# ATmega16HVA register map
Vendor: Atmel; File version: 1.0
CPU: other r0p0, little endian, no MPU, no FPU, 4 interrupt priority bits
Registers are 8-bit, read-write, reset 0x0 unless marked. A register's access mark holds for its fields unless they carry their own. Offsets are from the block's base; [hi:lo] are bit positions.

## EXINT — External Interrupts
Base 0x0080003C
0x00 EIFR — External Interrupt Flag Register (read-only for debugger)
  [2:0] INTF — External Interrupt Flags
0x01 EIMSK — External Interrupt Mask Register
  [2:0] INT — External Interrupt Request 2 Enable
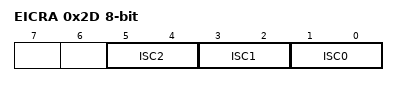
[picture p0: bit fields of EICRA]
0x2D EICRA — External Interrupt Control Register
  [all] fields
    0=LOW_LEVEL_OF_INTX; 1=ANY_LOGICAL_CHANGE_OF_INTX; 2=FALLING_EDGE_OF_INTX; 3=RISING_EDGE_OF_INTX
  [5:4] ISC2 — External Interrupt Sense Control 2 Bits
  [3:2] ISC1 — External Interrupt Sense Control 1 Bits
  [1:0] ISC0 — External Interrupt Sense Control 0 Bits

## FET — FET Control
Base 0x008000F0
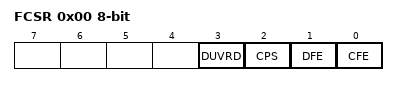
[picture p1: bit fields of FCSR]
0x00 FCSR — FET Control and Status Register
  [3] DUVRD — Deep Under-Voltage Recovery Disable
  [2] CPS — Current Protection Status
  [1] DFE — Discharge FET Enable
  [0] CFE — Charge FET Enable

## FUSE — Fuses
Base 0x00800000
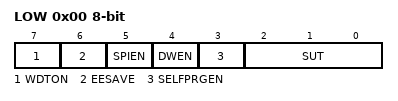
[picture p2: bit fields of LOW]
0x00 LOW
  [7] WDTON — Watch-dog Timer always on
  [6] EESAVE — Preserve EEPROM through the Chip Erase cycle
  [5] SPIEN — Serial program downloading (SPI) enabled
  [4] DWEN — Debug Wire enable
  [3] SELFPRGEN — Self Programming enable
  [2:0] SUT — Select start-up time
    0=6CK_14CK_4MS (Start-up time 6 CK/14 CK + 4 ms); 1=6CK_14CK_8MS (Start-up time 6 CK/14 CK + 8 ms); 2=6CK_14CK_16MS (Start-up time 6 CK/14 CK + 16 ms); 3=6CK_14CK_32MS (Start-up time 6 CK/14 CK + 32 ms); 4=6CK_14CK_64MS (Start-up time 6 CK/14 CK + 64 ms); 5=6CK_14CK_128MS (Start-up time 6 CK/14 CK + 128 ms); 6=6CK_14CK_256MS (Start-up time 6 CK/14 CK + 256 ms); 7=6CK_14CK_512MS (Start-up time 6 CK/14 CK + 512 ms)

## LOCKBIT — Lockbits
Base 0x00800000
0x00 LOCKBIT
  [1:0] LB — Memory Lock
    0=PROG_VER_DISABLED (Further programming and verification disabled); 2=PROG_DISABLED (Further programming disabled); 3=NO_LOCK (No memory lock features enabled)

## PORTA — I/O Port
Base 0x00800020
0x00 PINA — Port A Input Pins (read-only for debugger)
0x01 DDRA — Port A Data Direction Register
0x02 PORTA — Port A Data Register

## PORTB — I/O Port
Base 0x00800023
0x00 PINB — Input Pins, Port B (read-only for debugger)
0x01 DDRB — Data Direction Register, Port B
0x02 PORTB — Data Register, Port B

## PORTC — I/O Port
Base 0x00800026
0x00 PINC — Port C Input Pins (read-only for debugger)
0x02 PORTC — Port C Data Register

## SPI — Serial Peripheral Interface
Base 0x0080004C
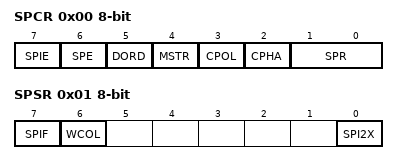
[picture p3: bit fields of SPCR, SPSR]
0x00 SPCR — SPI Control Register
  [7] SPIE — SPI Interrupt Enable
  [6] SPE — SPI Enable
  [5] DORD — Data Order
  [4] MSTR — Master/Slave Select
  [3] CPOL — Clock polarity
  [2] CPHA — Clock Phase
  [1:0] SPR — SPI Clock Rate Selects
    0=FOSC_4; 1=FOSC_16; 3=FOSC_128
0x01 SPSR — SPI Status Register (read-only for debugger)
  [7] SPIF — SPI Interrupt Flag
  [6] WCOL — Write Collision Flag
  [0] SPI2X — Double SPI Speed Bit
0x02 SPDR — SPI Data Register (write-only for debugger)

## TC0 — Timer/Counter, 16-bit
Base 0x00800035
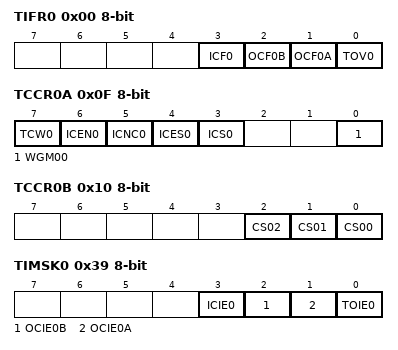
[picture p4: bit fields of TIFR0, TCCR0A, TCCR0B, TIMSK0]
0x00 TIFR0 — Timer/Counter Interrupt Flag register (read-only for debugger)
  [3] ICF0 — Timer/Counter Interrupt Flag Register
  [2] OCF0B — Output Compare Flag
  [1] OCF0A — Output Compare Flag
  [0] TOV0 — Overflow Flag
0x0F TCCR0A — Timer/Counter0 Control Register
  [7] TCW0 — Timer/Counter Width
  [6] ICEN0 — Input Capture Mode Enable
  [5] ICNC0 — Input Capture Noise Canceler
  [4] ICES0 — Input Capture Edge Select
  [3] ICS0 — Input Capture Select
  [0] WGM00 — Clock Select0 bit 0
0x10 TCCR0B — Timer/Counter0 Control Register
  [2] CS02 — Clock Select0 bit 2
  [1] CS01 — Clock Select0 bit 1
  [0] CS00 — Clock Select0 bit 0
0x11 TCNT0 16-bit (reset mask 0xFF) — Timer Counter 0 Bytes
0x13 OCR0A — Output compare Register A
0x14 OCR0B — Output compare Register B
0x39 TIMSK0 — Timer/Counter Interrupt Mask Register
  [3] ICIE0 — Timer/Counter n Input Capture Interrupt Enable
  [2] OCIE0B — Output Compare Interrupt Enable
  [1] OCIE0A — Output Compare Interrupt Enable
  [0] TOIE0 — Overflow Interrupt Enable

## TC1 — Timer/Counter, 16-bit
Base 0x00800036
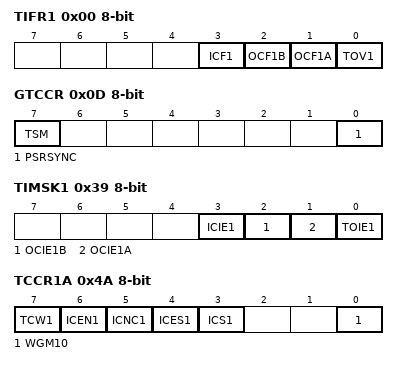
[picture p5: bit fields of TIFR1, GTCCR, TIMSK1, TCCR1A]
0x00 TIFR1 — Timer/Counter Interrupt Flag register (read-only for debugger)
  [3] ICF1 — Timer/Counter 1 Input Capture Flag
  [2] OCF1B — Timer/Counter1 Output Compare Flag B
  [1] OCF1A — Timer/Counter1 Output Compare Flag A
  [0] TOV1 — Timer/Counter1 Overflow Flag
0x0D GTCCR — General Timer/Counter Control Register
  [7] TSM — Timer/Counter Synchronization Mode
  [0] PSRSYNC — Prescaler Reset
0x39 TIMSK1 — Timer/Counter Interrupt Mask Register
  [3] ICIE1 — Timer/Counter n Input Capture Interrupt Enable
  [2] OCIE1B — Timer/Counter1 Output Compare B Interrupt Enable
  [1] OCIE1A — Timer/Counter1 Output Compare A Interrupt Enable
  [0] TOIE1 — Timer/Counter1 Overflow Interrupt Enable
0x4A TCCR1A — Timer/Counter 1 Control Register A
  [7] TCW1 — Timer/Counter Width
  [6] ICEN1 — Input Capture Mode Enable
  [5] ICNC1 — Input Capture Noise Canceler
  [4] ICES1 — Input Capture Edge Select
  [3] ICS1 — Input Capture Select
  [0] WGM10 — Waveform Generation Mode
0x4B TCCR1B — Timer/Counter1 Control Register B
  [2:0] CS — Clock Select1 bis
0x4E TCNT1 16-bit (reset mask 0xFF) — Timer Counter 1 Bytes
0x52 OCR1A — Output Compare Register 1A
0x53 OCR1B — Output Compare Register B

## VOLTAGE_REGULATOR
Base 0x008000C8
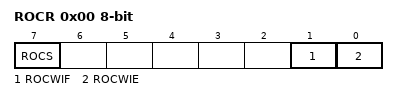
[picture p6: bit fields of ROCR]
0x00 ROCR — Regulator Operating Condition Register (read-only for debugger)
  [7] ROCS — ROC Status
  [1] ROCWIF — ROC Warning Interrupt Flag
  [0] ROCWIE — ROC Warning Interrupt Enable

## WDT — Watchdog Timer
Base 0x00800060
0x00 WDTCSR — Watchdog Timer Control Register (read-only for debugger)
  [7] WDIF — Watchdog Timeout Interrupt Flag
  [6] WDIE — Watchdog Timeout Interrupt Enable
  [4] WDCE — Watchdog Change Enable
  [3] WDE — Watch Dog Enable
  [5:0] WDP — Watchdog Timer Prescaler Bits
    0=OSCILLATOR_CYCLES_2K; 1=OSCILLATOR_CYCLES_4K; 2=OSCILLATOR_CYCLES_8K; 3=OSCILLATOR_CYCLES_16K; 4=OSCILLATOR_CYCLES_32K; 5=OSCILLATOR_CYCLES_64K; 6=OSCILLATOR_CYCLES_128K; 7=OSCILLATOR_CYCLES_256K
